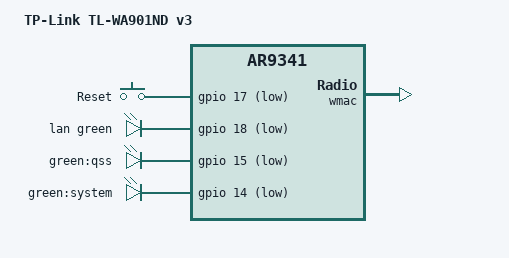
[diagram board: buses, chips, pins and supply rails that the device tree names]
// SPDX-License-Identifier: GPL-2.0-or-later OR MIT

#include <dt-bindings/leds/common.h>

#include "ar9341_tplink_tl-wa.dtsi"

/ {
	model = "TP-Link TL-WA901ND v3";
	compatible = "tplink,tl-wa901nd-v3", "qca,ar9341";

	aliases {
		led-boot = &led_system;
		led-failsafe = &led_system;
		led-running = &led_system;
		led-upgrade = &led_system;
	};

	keys {
		compatible = "gpio-keys";

		reset {
			label = "Reset";
			linux,code = <KEY_RESTART>;
			gpios = <&gpio 17 GPIO_ACTIVE_LOW>;
			debounce-interval = <60>;
		};
	};

	leds {
		compatible = "gpio-leds";

		lan {
			function = LED_FUNCTION_LAN;
			color = <LED_COLOR_ID_GREEN>;
			gpios = <&gpio 18 GPIO_ACTIVE_LOW>;
		};

		qss {
			label = "green:qss";
			gpios = <&gpio 15 GPIO_ACTIVE_LOW>;
		};

		led_system: system {
			label = "green:system";
			gpios = <&gpio 14 GPIO_ACTIVE_LOW>;
		};
	};
};

&wmac {
	led {
		led-sources = <13>;
		led-active-low;
	};
};
